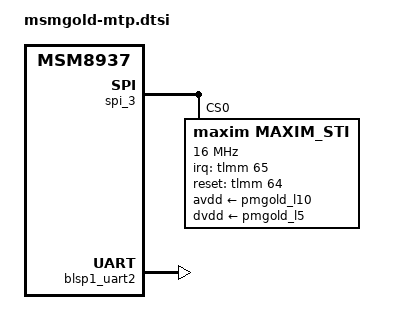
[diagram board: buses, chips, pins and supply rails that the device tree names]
/*
 * Copyright (c) 2015, The Linux Foundation. All rights reserved.
 *
 * This program is free software; you can redistribute it and/or modify
 * it under the terms of the GNU General Public License version 2 and
 * only version 2 as published by the Free Software Foundation.
 *
 * This program is distributed in the hope that it will be useful,
 * but WITHOUT ANY WARRANTY; without even the implied warranty of
 * MERCHANTABILITY or FITNESS FOR A PARTICULAR PURPOSE.  See the
 * GNU General Public License for more details.
 */

#include "msmgold-pinctrl.dtsi"
#include "msmgold-camera-sensor-mtp.dtsi"

&spi_3 { /* BLSP1 QUP3 */
	spi-max-frequency = <16000000>;
	status = "ok";
	maxim_sti@0 {
		compatible = "maxim,maxim_sti";
		reg = <0>;
		interrupt-parent = <&tlmm>;
		interrupts = <65 0>;
		spi-max-frequency = <16000000>;
		avdd-supply = <&pmgold_l10>;
		dvdd-supply = <&pmgold_l5>;
		maxim_sti,irq-gpio = <&tlmm 65 0x00>;
		maxim_sti,reset-gpio = <&tlmm 64 0x00>;
		maxim_sti,touch_fusion = "/vendor/bin/touch_fusion";
		maxim_sti,config_file = "/etc/firmware/qtc800s.cfg";
		maxim_sti,fw_name = "qtc800s.bin";
		pinctrl-names = "pmx_ts_active","pmx_ts_suspend",
			"pmx_ts_release";
		pinctrl-0 = <&ts_int_active &ts_reset_active>;
		pinctrl-1 = <&ts_int_suspend &ts_reset_suspend>;
		pinctrl-2 = <&ts_release>;
	};
};

&soc {
};

&blsp1_uart2 {
	status = "ok";
	pinctrl-names = "default";
	pinctrl-0 = <&uart_console_active>;
};

#include "msm8937-mdss-panels.dtsi"

&mdss_mdp {
	qcom,mdss-pref-prim-intf = "dsi";
};

&mdss_dsi {
	hw-config = "single_dsi";
};

&mdss_dsi0 {
	qcom,dsi-pref-prim-pan = <&dsi_truly_720_vid>;
	pinctrl-names = "mdss_default", "mdss_sleep";
	pinctrl-0 = <&mdss_dsi_active &mdss_te_active>;
	pinctrl-1 = <&mdss_dsi_suspend &mdss_te_suspend>;

	qcom,platform-te-gpio = <&tlmm 24 0>;
	qcom,platform-enable-gpio = <&tlmm 99 0>;
	qcom,platform-reset-gpio = <&tlmm 60 0>;
	qcom,platform-bklight-en-gpio = <&tlmm 98 0>;
};

&dsi_truly_720_vid {
	qcom,panel-supply-entries = <&dsi_panel_pwr_supply>;
};
